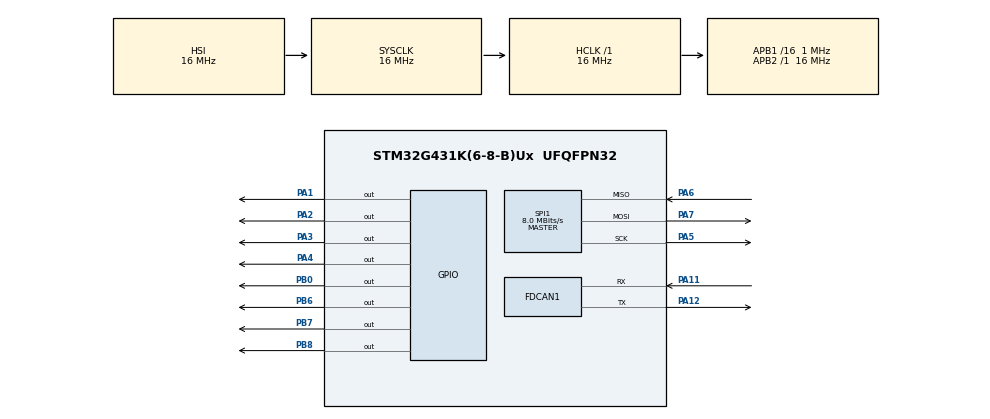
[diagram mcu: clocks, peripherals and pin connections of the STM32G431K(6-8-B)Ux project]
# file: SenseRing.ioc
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FDCAN1.AutoRetransmission=ENABLE
FDCAN1.CalculateBaudRateNominal=31250
FDCAN1.CalculateTimeBitNominal=32000
FDCAN1.CalculateTimeQuantumNominal=1000.0
FDCAN1.ClockDivider=FDCAN_CLOCK_DIV1
FDCAN1.DataSyncJumpWidth=15
FDCAN1.DataTimeSeg1=16
FDCAN1.DataTimeSeg2=15
FDCAN1.FrameFormat=FDCAN_FRAME_FD_BRS
FDCAN1.Mode=FDCAN_MODE_EXTERNAL_LOOPBACK
FDCAN1.NominalPrescaler=1
FDCAN1.NominalSyncJumpWidth=5
FDCAN1.NominalTimeSeg1=26
FDCAN1.NominalTimeSeg2=5
Mcu.Family=STM32G4
Mcu.Name=STM32G431K(6-8-B)Ux
Mcu.Package=UFQFPN32
NVIC.PriorityGroup=NVIC_PRIORITYGROUP_4
PA1.Signal=GPIO_Output
PA11.Mode=FDCAN_Activate
PA11.Signal=FDCAN1_RX
PA12.Mode=FDCAN_Activate
PA12.Signal=FDCAN1_TX
PA13.Mode=Trace_Asynchronous_SW
PA13.Signal=SYS_JTMS-SWDIO
PA14.Mode=Trace_Asynchronous_SW
PA14.Signal=SYS_JTCK-SWCLK
PA2.Signal=GPIO_Output
PA3.Signal=GPIO_Output
PA4.Signal=GPIO_Output
PA5.Mode=Full_Duplex_Master
PA5.Signal=SPI1_SCK
PA6.Mode=Full_Duplex_Master
PA6.Signal=SPI1_MISO
PA7.Mode=Full_Duplex_Master
PA7.Signal=SPI1_MOSI
PB0.Signal=GPIO_Output
PB3.Mode=Trace_Asynchronous_SW
PB3.Signal=SYS_JTDO-SWO
PB6.Signal=GPIO_Output
PB7.Signal=GPIO_Output
PB8-BOOT0.Signal=GPIO_Output
PF0-OSC_IN.Mode=HSE-External-Oscillator
PF0-OSC_IN.Signal=RCC_OSC_IN
PF1-OSC_OUT.Mode=HSE-External-Oscillator
PF1-OSC_OUT.Signal=RCC_OSC_OUT
ProjectManager.HeapSize=0x200
ProjectManager.StackSize=0x400
ProjectManager.TargetToolchain=STM32CubeIDE
RCC.AHBFreq_Value=16000000
RCC.APB1CLKDivider=RCC_HCLK_DIV16
RCC.APB1Freq_Value=1000000
RCC.APB1TimFreq_Value=2000000
RCC.APB2Freq_Value=16000000
RCC.APB2TimFreq_Value=16000000
RCC.CortexFreq_Value=16000000
RCC.EXTERNAL_CLOCK_VALUE=12288000
RCC.HCLKFreq_Value=16000000
RCC.HSE_VALUE=16000000
RCC.HSI48_VALUE=48000000
RCC.HSI_VALUE=16000000
RCC.LSE_VALUE=32768
RCC.PLLSourceVirtual=RCC_PLLSOURCE_HSE
RCC.SYSCLKFreq_VALUE=16000000
RCC.USBFreq_Value=64000000
RCC.VCOOutputFreq_Value=128000000
SPI1.CalculateBaudRate=8.0 MBits/s
SPI1.Direction=SPI_DIRECTION_2LINES
SPI1.Mode=SPI_MODE_MASTER
SPI1.VirtualType=VM_MASTER
VP_SYS_VS_DBSignals.Mode=DisableDeadBatterySignals
board=custom

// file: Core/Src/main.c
/* USER CODE BEGIN Header */
/**
  ******************************************************************************
  * @file           : main.c
  * @brief          : Main program body
  ******************************************************************************
  * @attention
  *
  * Copyright (c) 2025 STMicroelectronics.
  * All rights reserved.
  *
  * This software is licensed under terms that can be found in the LICENSE file
  * in the root directory of this software component.
  * If no LICENSE file comes with this software, it is provided AS-IS.
  *
  ******************************************************************************
  */
/* USER CODE END Header */
#include "main.h"

/* USER CODE BEGIN Includes */
#include "App.h"
#include "lps22hh_reg.h"
/* USER CODE END Includes */

FDCAN_HandleTypeDef hfdcan1;

SPI_HandleTypeDef hspi1;

void SystemClock_Config(void);
static void MX_GPIO_Init(void);
static void MX_FDCAN1_Init(void);
static void MX_SPI1_Init(void);

int main(void)
{

  /* MCU Configuration--------------------------------------------------------*/

  /* Reset of all peripherals, Initializes the Flash interface and the Systick. */
  HAL_Init();

  /* Configure the system clock */
  SystemClock_Config();

  /* Initialize all configured peripherals */
  MX_GPIO_Init();
  MX_FDCAN1_Init();
  MX_SPI1_Init();
  /* USER CODE BEGIN 2 */
  App_Init();
  /* USER CODE END 2 */

  /* Infinite loop */
  while (1)
  {
	  App_Update();
  }
}

void SystemClock_Config(void)
{
  RCC_OscInitTypeDef RCC_OscInitStruct = {0};
  RCC_ClkInitTypeDef RCC_ClkInitStruct = {0};

  /** Configure the main internal regulator output voltage
  */
  HAL_PWREx_ControlVoltageScaling(PWR_REGULATOR_VOLTAGE_SCALE1);

  /** Initializes the RCC Oscillators according to the specified parameters
  * in the RCC_OscInitTypeDef structure.
  */
  RCC_OscInitStruct.OscillatorType = RCC_OSCILLATORTYPE_HSI;
  RCC_OscInitStruct.HSIState = RCC_HSI_ON;
  RCC_OscInitStruct.HSICalibrationValue = RCC_HSICALIBRATION_DEFAULT;
  RCC_OscInitStruct.PLL.PLLState = RCC_PLL_NONE;
  if (HAL_RCC_OscConfig(&RCC_OscInitStruct) != HAL_OK)
  {
    Error_Handler();
  }

  /** Initializes the CPU, AHB and APB buses clocks
  */
  RCC_ClkInitStruct.ClockType = RCC_CLOCKTYPE_HCLK|RCC_CLOCKTYPE_SYSCLK
                              |RCC_CLOCKTYPE_PCLK1|RCC_CLOCKTYPE_PCLK2;
  RCC_ClkInitStruct.SYSCLKSource = RCC_SYSCLKSOURCE_HSI;
  RCC_ClkInitStruct.AHBCLKDivider = RCC_SYSCLK_DIV1;
  RCC_ClkInitStruct.APB1CLKDivider = RCC_HCLK_DIV16;
  RCC_ClkInitStruct.APB2CLKDivider = RCC_HCLK_DIV1;

  if (HAL_RCC_ClockConfig(&RCC_ClkInitStruct, FLASH_LATENCY_0) != HAL_OK)
  {
    Error_Handler();
  }
}

static void MX_FDCAN1_Init(void)
{

  hfdcan1.Instance = FDCAN1;
  hfdcan1.Init.ClockDivider = FDCAN_CLOCK_DIV1;
  hfdcan1.Init.FrameFormat = FDCAN_FRAME_FD_BRS;
  hfdcan1.Init.Mode = FDCAN_MODE_EXTERNAL_LOOPBACK;
  hfdcan1.Init.AutoRetransmission = ENABLE;
  hfdcan1.Init.TransmitPause = DISABLE;
  hfdcan1.Init.ProtocolException = DISABLE;
  hfdcan1.Init.NominalPrescaler = 1;
  hfdcan1.Init.NominalSyncJumpWidth = 5;
  hfdcan1.Init.NominalTimeSeg1 = 26;
  hfdcan1.Init.NominalTimeSeg2 = 5;
  hfdcan1.Init.DataPrescaler = 1;
  hfdcan1.Init.DataSyncJumpWidth = 15;
  hfdcan1.Init.DataTimeSeg1 = 16;
  hfdcan1.Init.DataTimeSeg2 = 15;
  hfdcan1.Init.StdFiltersNbr = 0;
  hfdcan1.Init.ExtFiltersNbr = 0;
  hfdcan1.Init.TxFifoQueueMode = FDCAN_TX_FIFO_OPERATION;
  if (HAL_FDCAN_Init(&hfdcan1) != HAL_OK)
  {
    Error_Handler();
  }

}

static void MX_SPI1_Init(void)
{

  /* SPI1 parameter configuration*/
  hspi1.Instance = SPI1;
  hspi1.Init.Mode = SPI_MODE_MASTER;
  hspi1.Init.Direction = SPI_DIRECTION_2LINES;
  hspi1.Init.DataSize = SPI_DATASIZE_4BIT;
  hspi1.Init.CLKPolarity = SPI_POLARITY_LOW;
  hspi1.Init.CLKPhase = SPI_PHASE_1EDGE;
  hspi1.Init.NSS = SPI_NSS_SOFT;
  hspi1.Init.BaudRatePrescaler = SPI_BAUDRATEPRESCALER_2;
  hspi1.Init.FirstBit = SPI_FIRSTBIT_MSB;
  hspi1.Init.TIMode = SPI_TIMODE_DISABLE;
  hspi1.Init.CRCCalculation = SPI_CRCCALCULATION_DISABLE;
  hspi1.Init.CRCPolynomial = 7;
  hspi1.Init.CRCLength = SPI_CRC_LENGTH_DATASIZE;
  hspi1.Init.NSSPMode = SPI_NSS_PULSE_ENABLE;
  if (HAL_SPI_Init(&hspi1) != HAL_OK)
  {
    Error_Handler();
  }

}

static void MX_GPIO_Init(void)
{
  GPIO_InitTypeDef GPIO_InitStruct = {0};

  /* GPIO Ports Clock Enable */
  __HAL_RCC_GPIOF_CLK_ENABLE();
  __HAL_RCC_GPIOA_CLK_ENABLE();
  __HAL_RCC_GPIOB_CLK_ENABLE();

  /*Configure GPIO pin Output Level */
  HAL_GPIO_WritePin(GPIOA, GPIO_PIN_1|GPIO_PIN_2|GPIO_PIN_3|GPIO_PIN_4, GPIO_PIN_RESET);

  /*Configure GPIO pin Output Level */
  HAL_GPIO_WritePin(GPIOB, GPIO_PIN_0|GPIO_PIN_6|GPIO_PIN_7|GPIO_PIN_8, GPIO_PIN_RESET);

  /*Configure GPIO pins : PA1 PA2 PA3 PA4 */
  GPIO_InitStruct.Pin = GPIO_PIN_1|GPIO_PIN_2|GPIO_PIN_3|GPIO_PIN_4;
  GPIO_InitStruct.Mode = GPIO_MODE_OUTPUT_PP;
  GPIO_InitStruct.Pull = GPIO_NOPULL;
  GPIO_InitStruct.Speed = GPIO_SPEED_FREQ_LOW;
  HAL_GPIO_Init(GPIOA, &GPIO_InitStruct);

  /*Configure GPIO pins : PB0 PB6 PB7 PB8 */
  GPIO_InitStruct.Pin = GPIO_PIN_0|GPIO_PIN_6|GPIO_PIN_7|GPIO_PIN_8;
  GPIO_InitStruct.Mode = GPIO_MODE_OUTPUT_PP;
  GPIO_InitStruct.Pull = GPIO_NOPULL;
  GPIO_InitStruct.Speed = GPIO_SPEED_FREQ_LOW;
  HAL_GPIO_Init(GPIOB, &GPIO_InitStruct);

}

void Error_Handler(void)
{
  __disable_irq();
  while (1)
  {
  }
}
